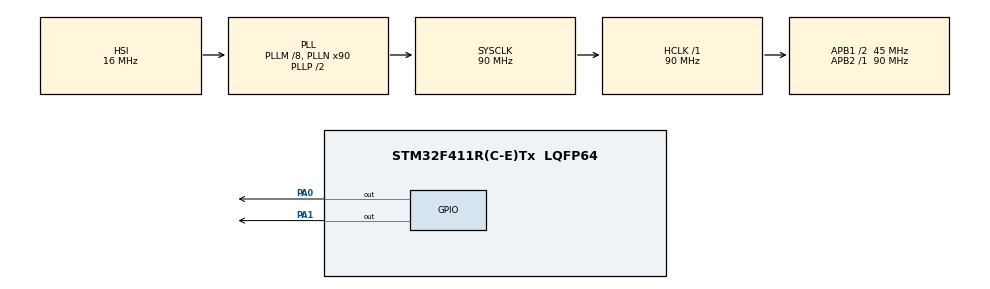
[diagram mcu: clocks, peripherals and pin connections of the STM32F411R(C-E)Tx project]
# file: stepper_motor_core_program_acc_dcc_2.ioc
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Mcu.Family=STM32F4
Mcu.Name=STM32F411R(C-E)Tx
Mcu.Package=LQFP64
NVIC.PriorityGroup=NVIC_PRIORITYGROUP_0
PA0-WKUP.Signal=GPIO_Output
PA1.Signal=GPIO_Output
ProjectManager.HeapSize=0x200
ProjectManager.StackSize=0x400
ProjectManager.TargetToolchain=STM32CubeIDE
RCC.48MHZClocksFreq_Value=45000000
RCC.AHBFreq_Value=90000000
RCC.APB1CLKDivider=RCC_HCLK_DIV2
RCC.APB1Freq_Value=45000000
RCC.APB1TimFreq_Value=90000000
RCC.APB2Freq_Value=90000000
RCC.APB2TimFreq_Value=90000000
RCC.CortexFreq_Value=90000000
RCC.FLatency-AdvancedSettings=FLASH_LATENCY_2
RCC.HCLKFreq_Value=90000000
RCC.HSE_VALUE=8000000
RCC.HSI_VALUE=16000000
RCC.LSE_VALUE=32768
RCC.PLLM=8
RCC.PLLN=90
RCC.SYSCLKFreq_VALUE=90000000
RCC.SYSCLKSource=RCC_SYSCLKSOURCE_PLLCLK
RCC.VCOOutputFreq_Value=180000000
TIM1.Prescaler=100
VP_TIM1_VS_ClockSourceINT.Mode=Internal
board=NUCLEO-F411RE

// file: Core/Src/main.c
/* USER CODE BEGIN Header */
/**
  ******************************************************************************
  * @file           : main.c
  * @brief          : Main program body
  ******************************************************************************
  * @attention
  *
  * Copyright (c) 2024 STMicroelectronics.
  * All rights reserved.
  *
  * This software is licensed under terms that can be found in the LICENSE file
  * in the root directory of this software component.
  * If no LICENSE file comes with this software, it is provided AS-IS.
  *
  ******************************************************************************
  */
/* USER CODE END Header */
#include "main.h"

/* USER CODE BEGIN Includes */
#include <PlebcStepper.h>
int rpm = 50;
int steps = 6400;
/* USER CODE END Includes */

TIM_HandleTypeDef htim1;

void SystemClock_Config(void);
static void MX_GPIO_Init(void);
static void MX_TIM1_Init(void);

int main(void)
{

  /* MCU Configuration--------------------------------------------------------*/

  /* Reset of all peripherals, Initializes the Flash interface and the Systick. */
  HAL_Init();

  /* Configure the system clock */
  SystemClock_Config();

  /* Initialize all configured peripherals */
  MX_GPIO_Init();
  MX_TIM1_Init();
  /* USER CODE BEGIN 2 */
	  HAL_TIM_Base_Start(&htim1); // Start the timer

	  // Define motor configurations
	  MotorConfig motor1 = {GPIOA, GPIO_PIN_1, GPIOA, GPIO_PIN_0};

	  // Setup stepper motor parameters
	  setRPM(rpm,steps); // (RPM, Steps)
	  setAcceleration(50.0); // Set acceleration in steps per second^2

//	  motorRunContinuous(&motor1); 	//Run the motor continuously
//	  motorRunForward(&motor1);		// Motor run forward direction
//	  motorRunBackward(&motor1);	// Motor run backward direction
//	  motorStop(&motor1);
//	  emergencyMotorStop(&motor1);
	  motorMove(&motor1,6400);

  /* USER CODE END 2 */

  /* Infinite loop */
  while (1)
  {

  }
}

void SystemClock_Config(void)
{
  RCC_OscInitTypeDef RCC_OscInitStruct = {0};
  RCC_ClkInitTypeDef RCC_ClkInitStruct = {0};

  /** Configure the main internal regulator output voltage
  */
  __HAL_RCC_PWR_CLK_ENABLE();
  __HAL_PWR_VOLTAGESCALING_CONFIG(PWR_REGULATOR_VOLTAGE_SCALE1);

  /** Initializes the RCC Oscillators according to the specified parameters
  * in the RCC_OscInitTypeDef structure.
  */
  RCC_OscInitStruct.OscillatorType = RCC_OSCILLATORTYPE_HSI;
  RCC_OscInitStruct.HSIState = RCC_HSI_ON;
  RCC_OscInitStruct.HSICalibrationValue = RCC_HSICALIBRATION_DEFAULT;
  RCC_OscInitStruct.PLL.PLLState = RCC_PLL_ON;
  RCC_OscInitStruct.PLL.PLLSource = RCC_PLLSOURCE_HSI;
  RCC_OscInitStruct.PLL.PLLM = 8;
  RCC_OscInitStruct.PLL.PLLN = 90;
  RCC_OscInitStruct.PLL.PLLP = RCC_PLLP_DIV2;
  RCC_OscInitStruct.PLL.PLLQ = 4;
  if (HAL_RCC_OscConfig(&RCC_OscInitStruct) != HAL_OK)
  {
    Error_Handler();
  }

  /** Initializes the CPU, AHB and APB buses clocks
  */
  RCC_ClkInitStruct.ClockType = RCC_CLOCKTYPE_HCLK|RCC_CLOCKTYPE_SYSCLK
                              |RCC_CLOCKTYPE_PCLK1|RCC_CLOCKTYPE_PCLK2;
  RCC_ClkInitStruct.SYSCLKSource = RCC_SYSCLKSOURCE_PLLCLK;
  RCC_ClkInitStruct.AHBCLKDivider = RCC_SYSCLK_DIV1;
  RCC_ClkInitStruct.APB1CLKDivider = RCC_HCLK_DIV2;
  RCC_ClkInitStruct.APB2CLKDivider = RCC_HCLK_DIV1;

  if (HAL_RCC_ClockConfig(&RCC_ClkInitStruct, FLASH_LATENCY_2) != HAL_OK)
  {
    Error_Handler();
  }
}

static void MX_TIM1_Init(void)
{

  TIM_ClockConfigTypeDef sClockSourceConfig = {0};
  TIM_MasterConfigTypeDef sMasterConfig = {0};

  htim1.Instance = TIM1;
  htim1.Init.Prescaler = 100;
  htim1.Init.CounterMode = TIM_COUNTERMODE_UP;
  htim1.Init.Period = 65535;
  htim1.Init.ClockDivision = TIM_CLOCKDIVISION_DIV1;
  htim1.Init.RepetitionCounter = 0;
  htim1.Init.AutoReloadPreload = TIM_AUTORELOAD_PRELOAD_DISABLE;
  if (HAL_TIM_Base_Init(&htim1) != HAL_OK)
  {
    Error_Handler();
  }
  sClockSourceConfig.ClockSource = TIM_CLOCKSOURCE_INTERNAL;
  if (HAL_TIM_ConfigClockSource(&htim1, &sClockSourceConfig) != HAL_OK)
  {
    Error_Handler();
  }
  sMasterConfig.MasterOutputTrigger = TIM_TRGO_RESET;
  sMasterConfig.MasterSlaveMode = TIM_MASTERSLAVEMODE_DISABLE;
  if (HAL_TIMEx_MasterConfigSynchronization(&htim1, &sMasterConfig) != HAL_OK)
  {
    Error_Handler();
  }

}

static void MX_GPIO_Init(void)
{
  GPIO_InitTypeDef GPIO_InitStruct = {0};

  /* GPIO Ports Clock Enable */
  __HAL_RCC_GPIOA_CLK_ENABLE();

  /*Configure GPIO pin Output Level */
  HAL_GPIO_WritePin(GPIOA, GPIO_PIN_0|GPIO_PIN_1, GPIO_PIN_RESET);

  /*Configure GPIO pins : PA0 PA1 */
  GPIO_InitStruct.Pin = GPIO_PIN_0|GPIO_PIN_1;
  GPIO_InitStruct.Mode = GPIO_MODE_OUTPUT_PP;
  GPIO_InitStruct.Pull = GPIO_NOPULL;
  GPIO_InitStruct.Speed = GPIO_SPEED_FREQ_LOW;
  HAL_GPIO_Init(GPIOA, &GPIO_InitStruct);

}

void Error_Handler(void)
{
  __disable_irq();
  while (1)
  {
  }
}
